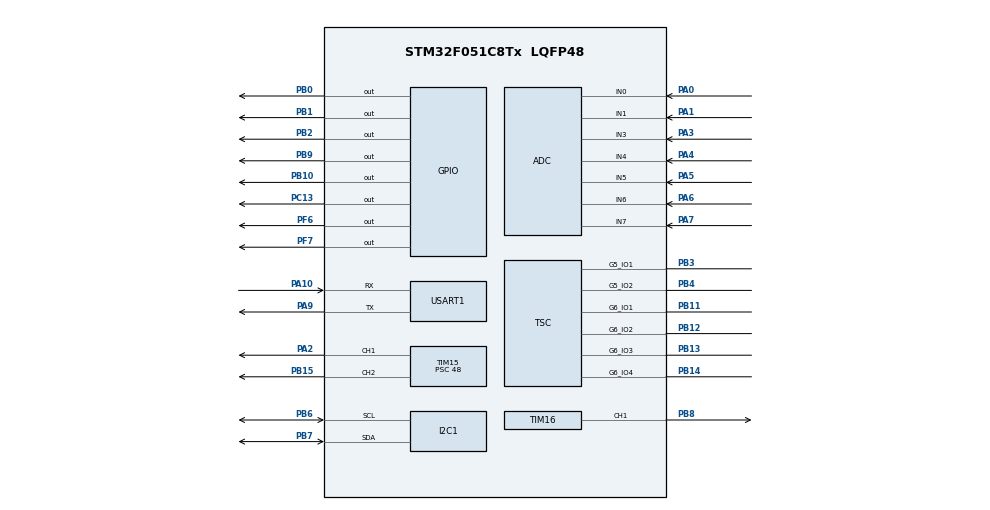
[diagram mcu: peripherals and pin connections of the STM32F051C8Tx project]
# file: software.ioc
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Mcu.Family=STM32F0
Mcu.Name=STM32F051C8Tx
Mcu.Package=LQFP48
Mcu.UserConstants=RS485_DE_HW_ENABLE,0
NVIC.USART1_IRQn=true\:0\:0\:false\:false\:true\:true
PA0.Mode=IN0
PA0.Signal=ADC_IN0
PA1.Mode=IN1
PA1.Signal=ADC_IN1
PA10.Mode=Asynchronous
PA10.Signal=USART1_RX
PA13.Mode=Serial_Wire
PA13.Signal=SYS_SWDIO
PA14.Mode=Serial_Wire
PA14.Signal=SYS_SWCLK
PA2.Signal=S_TIM15_CH1
PA3.Mode=IN3
PA3.Signal=ADC_IN3
PA4.Mode=IN4
PA4.Signal=ADC_IN4
PA5.Mode=IN5
PA5.Signal=ADC_IN5
PA6.Mode=IN6
PA6.Signal=ADC_IN6
PA7.Mode=IN7
PA7.Signal=ADC_IN7
PA9.Mode=Asynchronous
PA9.Signal=USART1_TX
PB0.Signal=GPIO_Output
PB1.Signal=GPIO_Output
PB10.Signal=GPIO_Output
PB11.Mode=G6_IO1-Sampling
PB11.Signal=TSC_G6_IO1
PB12.Mode=G6_IO2-Channel
PB12.Signal=TSC_G6_IO2
PB13.Mode=G6_IO3-Channel
PB13.Signal=TSC_G6_IO3
PB14.Mode=G6_IO4-Channel
PB14.Signal=TSC_G6_IO4
PB15.Signal=S_TIM15_CH2
PB2.Signal=GPIO_Output
PB3.Mode=G5_IO1-Sampling
PB3.Signal=TSC_G5_IO1
PB4.Mode=G5_IO2-Channel
PB4.Signal=TSC_G5_IO2
PB6.Mode=I2C
PB6.Signal=I2C1_SCL
PB7.Mode=I2C
PB7.Signal=I2C1_SDA
PB8.Signal=S_TIM16_CH1
PB9.Signal=GPIO_Output
PC13.Signal=GPIO_Output
PC14-OSC32_IN.Mode=LSE-External-Oscillator
PC14-OSC32_IN.Signal=RCC_OSC32_IN
PC15-OSC32_OUT.Mode=LSE-External-Oscillator
PC15-OSC32_OUT.Signal=RCC_OSC32_OUT
PF0-OSC_IN.Mode=HSE-External-Oscillator
PF0-OSC_IN.Signal=RCC_OSC_IN
PF1-OSC_OUT.Mode=HSE-External-Oscillator
PF1-OSC_OUT.Signal=RCC_OSC_OUT
PF6.Signal=GPIO_Output
PF7.Signal=GPIO_Output
ProjectManager.HeapSize=0x200
ProjectManager.StackSize=0x400
ProjectManager.TargetToolchain=Other Toolchains (GPDSC)
RCC.AHBFreq_Value=48000000
RCC.APB1Freq_Value=48000000
RCC.APB1TimFreq_Value=48000000
RCC.FLatency=FLASH_LATENCY_1
RCC.HCLKFreq_Value=48000000
RCC.PLLMUL=RCC_PLL_MUL6
RCC.PLLSourceVirtual=RCC_PLLSOURCE_HSE
RCC.RCC_MCOSource=RCC_MCO1SOURCE_PLLCLK_DIV2
RCC.SYSCLKFreq_VALUE=48000000
RCC.SYSCLKSource=RCC_SYSCLKSOURCE_PLLCLK
RCC.Usart1ClockSelection=RCC_USART1CLKSOURCE_SYSCLK
SH.S_TIM15_CH1.0=TIM15_CH1,PWM Generation1 CH1
SH.S_TIM15_CH2.0=TIM15_CH2,PWM Generation2 CH2
SH.S_TIM16_CH1.0=TIM16_CH1,PWM Generation1 CH1
TIM15.Channel-PWM\ Generation1\ CH1=TIM_CHANNEL_1
TIM15.Channel-PWM\ Generation2\ CH2=TIM_CHANNEL_2
TIM15.Period=1000
TIM15.Prescaler=48
TIM16.Channel=TIM_CHANNEL_1
TOUCHSENSING.IO_TOUCHKEY_B1=G5_IO2
TOUCHSENSING.IO_TOUCHKEY_B2=G6_IO2
TOUCHSENSING.IO_TOUCHKEY_B3=G6_IO3
TOUCHSENSING.IO_TOUCHKEY_B4=G6_IO4
TOUCHSENSING.TSLPRM_SENSORS_DATAS=TSLPRM_TOTAL_TOUCHKEYS_B 3 2 1 1 
TOUCHSENSING.TSLPRM_TOTAL_TOUCHKEYS_B=4
TSC.ChannelIOs-G5_IO2-Channel=TSC_GROUP5_IO2
TSC.ChannelIOs-G6_IO2-Channel=TSC_GROUP6_IO2
TSC.ChannelIOs-G6_IO3-Channel=TSC_GROUP6_IO3
TSC.ChannelIOs-G6_IO4-Channel=TSC_GROUP6_IO4
TSC.SamplingIOs-G5_IO1-Sampling=TSC_GROUP5_IO1
TSC.SamplingIOs-G6_IO1-Sampling=TSC_GROUP6_IO1
USART1.VirtualMode-Asynchronous=VM_ASYNC
VP_TIM16_VS_ClockSourceINT.Mode=Enable_Timer
VP_TOUCHSENSING_VS_TOUCHSENSING.Mode=TouchSensing_Enabled
board=template

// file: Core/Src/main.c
/**
  ******************************************************************************
  * @file           : main.c
  * @brief          : Main program body
  ******************************************************************************
  * This notice applies to any and all portions of this file
  * that are not between comment pairs USER CODE BEGIN and
  * USER CODE END. Other portions of this file, whether
  * inserted by the user or by software development tools
  * are owned by their respective copyright owners.
  *
  * Copyright (c) 2018 STMicroelectronics International N.V.
  * All rights reserved.
  *
  * Redistribution and use in source and binary forms, with or without
  * modification, are permitted, provided that the following conditions are met:
  *
  * 1. Redistribution of source code must retain the above copyright notice,
  *    this list of conditions and the following disclaimer.
  * 2. Redistributions in binary form must reproduce the above copyright notice,
  *    this list of conditions and the following disclaimer in the documentation
  *    and/or other materials provided with the distribution.
  * 3. Neither the name of STMicroelectronics nor the names of other
  *    contributors to this software may be used to endorse or promote products
  *    derived from this software without specific written permission.
  * 4. This software, including modifications and/or derivative works of this
  *    software, must execute solely and exclusively on microcontroller or
  *    microprocessor devices manufactured by or for STMicroelectronics.
  * 5. Redistribution and use of this software other than as permitted under
  *    this license is void and will automatically terminate your rights under
  *    this license.
  *
  * THIS SOFTWARE IS PROVIDED BY STMICROELECTRONICS AND CONTRIBUTORS "AS IS"
  * AND ANY EXPRESS, IMPLIED OR STATUTORY WARRANTIES, INCLUDING, BUT NOT
  * LIMITED TO, THE IMPLIED WARRANTIES OF MERCHANTABILITY, FITNESS FOR A
  * PARTICULAR PURPOSE AND NON-INFRINGEMENT OF THIRD PARTY INTELLECTUAL PROPERTY
  * RIGHTS ARE DISCLAIMED TO THE FULLEST EXTENT PERMITTED BY LAW. IN NO EVENT
  * SHALL STMICROELECTRONICS OR CONTRIBUTORS BE LIABLE FOR ANY DIRECT, INDIRECT,
  * INCIDENTAL, SPECIAL, EXEMPLARY, OR CONSEQUENTIAL DAMAGES (INCLUDING, BUT NOT
  * LIMITED TO, PROCUREMENT OF SUBSTITUTE GOODS OR SERVICES; LOSS OF USE, DATA,
  * OR PROFITS; OR BUSINESS INTERRUPTION) HOWEVER CAUSED AND ON ANY THEORY OF
  * LIABILITY, WHETHER IN CONTRACT, STRICT LIABILITY, OR TORT (INCLUDING
  * NEGLIGENCE OR OTHERWISE) ARISING IN ANY WAY OUT OF THE USE OF THIS SOFTWARE,
  * EVEN IF ADVISED OF THE POSSIBILITY OF SUCH DAMAGE.
  *
  ******************************************************************************
  */
#include "main.h"
#include "stm32f0xx_hal.h"
#include "touchsensing.h"

/* USER CODE BEGIN Includes */
#include "board.h"
/* USER CODE END Includes */

TSC_HandleTypeDef htsc;

/* USER CODE BEGIN PV */
volatile static uint32_t timestamp = 0, delay = 0;
/* Private variables ---------------------------------------------------------*/

/* USER CODE END PV */

void SystemClock_Config(void);
static void MX_GPIO_Init(void);
static void MX_I2C1_Init(void);
static void MX_USART1_UART_Init(void);
static void MX_TIM15_Init(void);
static void MX_TIM16_Init(void);
static void MX_TSC_Init(void);
static void MX_ADC_Init(void);

/* USER CODE BEGIN PFP */
/* Private function prototypes -----------------------------------------------*/

/* USER CODE END PFP */

int main(void)
{

  /* MCU Configuration----------------------------------------------------------*/

  /* Reset of all peripherals, Initializes the Flash interface and the Systick. */
  HAL_Init();

  /* Configure the system clock */
  SystemClock_Config();

  /* Initialize all configured peripherals */
  MX_GPIO_Init();
  MX_I2C1_Init();
  MX_USART1_UART_Init();
  MX_TIM15_Init();
  MX_TIM16_Init();
  MX_TSC_Init();
  MX_ADC_Init();
  MX_TOUCHSENSING_Init();
  /* USER CODE BEGIN 2 */

    UNI_Start();

    TSL_obj_GroupInit(&MyObjGroup);

  /* USER CODE END 2 */

  /* Infinite loop */
  /* USER CODE BEGIN WHILE */
  while (1)
  {
    timestamp = HAL_GetTick();

    if(delay < timestamp){

        delay = timestamp + 100;

        LED2_TOGGLE();
    }

    TSL_obj_GroupProcess(&MyObjGroup);
  /* USER CODE END WHILE */

  }

}

void SystemClock_Config(void)
{

  LL_FLASH_SetLatency(LL_FLASH_LATENCY_1);

  if(LL_FLASH_GetLatency() != LL_FLASH_LATENCY_1)
  {
  Error_Handler();
  }
  LL_RCC_HSE_Enable();

   /* Wait till HSE is ready */
  while(LL_RCC_HSE_IsReady() != 1)
  {

  }
  LL_RCC_HSI_Enable();

   /* Wait till HSI is ready */
  while(LL_RCC_HSI_IsReady() != 1)
  {

  }
  LL_RCC_HSI_SetCalibTrimming(16);

  LL_RCC_HSI14_Enable();

   /* Wait till HSI14 is ready */
  while(LL_RCC_HSI14_IsReady() != 1)
  {

  }
  LL_RCC_HSI14_SetCalibTrimming(16);

  LL_RCC_PLL_ConfigDomain_SYS(LL_RCC_PLLSOURCE_HSE_DIV_1, LL_RCC_PLL_MUL_6);

  LL_RCC_PLL_Enable();

   /* Wait till PLL is ready */
  while(LL_RCC_PLL_IsReady() != 1)
  {

  }
  LL_RCC_SetAHBPrescaler(LL_RCC_SYSCLK_DIV_1);

  LL_RCC_SetAPB1Prescaler(LL_RCC_APB1_DIV_1);

  LL_RCC_SetSysClkSource(LL_RCC_SYS_CLKSOURCE_PLL);

   /* Wait till System clock is ready */
  while(LL_RCC_GetSysClkSource() != LL_RCC_SYS_CLKSOURCE_STATUS_PLL)
  {

  }
  LL_Init1msTick(48000000);

  LL_SYSTICK_SetClkSource(LL_SYSTICK_CLKSOURCE_HCLK);

  LL_SetSystemCoreClock(48000000);

  LL_RCC_HSI14_EnableADCControl();

  LL_RCC_SetUSARTClockSource(LL_RCC_USART1_CLKSOURCE_SYSCLK);

  LL_RCC_SetI2CClockSource(LL_RCC_I2C1_CLKSOURCE_HSI);

  /* SysTick_IRQn interrupt configuration */
  NVIC_SetPriority(SysTick_IRQn, 0);
}

/* ADC init function */
static void MX_ADC_Init(void)
{

  LL_ADC_InitTypeDef ADC_InitStruct;
  LL_ADC_REG_InitTypeDef ADC_REG_InitStruct;

  LL_GPIO_InitTypeDef GPIO_InitStruct;

  /* Peripheral clock enable */
  LL_APB1_GRP2_EnableClock(LL_APB1_GRP2_PERIPH_ADC1);

  /**ADC GPIO Configuration
  PA0   ------> ADC_IN0
  PA1   ------> ADC_IN1
  PA3   ------> ADC_IN3
  PA4   ------> ADC_IN4
  PA5   ------> ADC_IN5
  PA6   ------> ADC_IN6
  PA7   ------> ADC_IN7
  */
  GPIO_InitStruct.Pin = LL_GPIO_PIN_0;
  GPIO_InitStruct.Mode = LL_GPIO_MODE_ANALOG;
  GPIO_InitStruct.Pull = LL_GPIO_PULL_NO;
  LL_GPIO_Init(GPIOA, &GPIO_InitStruct);

  GPIO_InitStruct.Pin = LL_GPIO_PIN_1;
  GPIO_InitStruct.Mode = LL_GPIO_MODE_ANALOG;
  GPIO_InitStruct.Pull = LL_GPIO_PULL_NO;
  LL_GPIO_Init(GPIOA, &GPIO_InitStruct);

  GPIO_InitStruct.Pin = LL_GPIO_PIN_3;
  GPIO_InitStruct.Mode = LL_GPIO_MODE_ANALOG;
  GPIO_InitStruct.Pull = LL_GPIO_PULL_NO;
  LL_GPIO_Init(GPIOA, &GPIO_InitStruct);

  GPIO_InitStruct.Pin = LL_GPIO_PIN_4;
  GPIO_InitStruct.Mode = LL_GPIO_MODE_ANALOG;
  GPIO_InitStruct.Pull = LL_GPIO_PULL_NO;
  LL_GPIO_Init(GPIOA, &GPIO_InitStruct);

  GPIO_InitStruct.Pin = LL_GPIO_PIN_5;
  GPIO_InitStruct.Mode = LL_GPIO_MODE_ANALOG;
  GPIO_InitStruct.Pull = LL_GPIO_PULL_NO;
  LL_GPIO_Init(GPIOA, &GPIO_InitStruct);

  GPIO_InitStruct.Pin = LL_GPIO_PIN_6;
  GPIO_InitStruct.Mode = LL_GPIO_MODE_ANALOG;
  GPIO_InitStruct.Pull = LL_GPIO_PULL_NO;
  LL_GPIO_Init(GPIOA, &GPIO_InitStruct);

  GPIO_InitStruct.Pin = LL_GPIO_PIN_7;
  GPIO_InitStruct.Mode = LL_GPIO_MODE_ANALOG;
  GPIO_InitStruct.Pull = LL_GPIO_PULL_NO;
  LL_GPIO_Init(GPIOA, &GPIO_InitStruct);

    /**Configure Regular Channel
    */
  LL_ADC_REG_SetSequencerChAdd(ADC1, LL_ADC_CHANNEL_0);

    /**Configure Regular Channel
    */
  LL_ADC_REG_SetSequencerChAdd(ADC1, LL_ADC_CHANNEL_1);

    /**Configure Regular Channel
    */
  LL_ADC_REG_SetSequencerChAdd(ADC1, LL_ADC_CHANNEL_3);

    /**Configure Regular Channel
    */
  LL_ADC_REG_SetSequencerChAdd(ADC1, LL_ADC_CHANNEL_4);

    /**Configure Regular Channel
    */
  LL_ADC_REG_SetSequencerChAdd(ADC1, LL_ADC_CHANNEL_5);

    /**Configure Regular Channel
    */
  LL_ADC_REG_SetSequencerChAdd(ADC1, LL_ADC_CHANNEL_6);

    /**Configure Regular Channel
    */
  LL_ADC_REG_SetSequencerChAdd(ADC1, LL_ADC_CHANNEL_7);

    /**Configure the global features of the ADC (Clock, Resolution, Data Alignment and number of conversion)
    */
  ADC_InitStruct.Clock = LL_ADC_CLOCK_ASYNC;
  ADC_InitStruct.Resolution = LL_ADC_RESOLUTION_12B;
  ADC_InitStruct.DataAlignment = LL_ADC_DATA_ALIGN_RIGHT;
  ADC_InitStruct.LowPowerMode = LL_ADC_LP_MODE_NONE;
  LL_ADC_Init(ADC1, &ADC_InitStruct);

  ADC_REG_InitStruct.TriggerSource = LL_ADC_REG_TRIG_SOFTWARE;
  ADC_REG_InitStruct.SequencerDiscont = LL_ADC_REG_SEQ_DISCONT_DISABLE;
  ADC_REG_InitStruct.ContinuousMode = LL_ADC_REG_CONV_SINGLE;
  ADC_REG_InitStruct.DMATransfer = LL_ADC_REG_DMA_TRANSFER_LIMITED;
  ADC_REG_InitStruct.Overrun = LL_ADC_REG_OVR_DATA_PRESERVED;
  LL_ADC_REG_Init(ADC1, &ADC_REG_InitStruct);

  LL_ADC_REG_SetSequencerScanDirection(ADC1, LL_ADC_REG_SEQ_SCAN_DIR_FORWARD);

  LL_ADC_SetSamplingTimeCommonChannels(ADC1, LL_ADC_SAMPLINGTIME_1CYCLE_5);

  LL_ADC_DisableIT_EOC(ADC1);

  LL_ADC_DisableIT_EOS(ADC1);

}

/* I2C1 init function */
static void MX_I2C1_Init(void)
{

  LL_I2C_InitTypeDef I2C_InitStruct;

  LL_GPIO_InitTypeDef GPIO_InitStruct;

  /**I2C1 GPIO Configuration
  PB6   ------> I2C1_SCL
  PB7   ------> I2C1_SDA
  */
  GPIO_InitStruct.Pin = LL_GPIO_PIN_6;
  GPIO_InitStruct.Mode = LL_GPIO_MODE_ALTERNATE;
  GPIO_InitStruct.Speed = LL_GPIO_SPEED_FREQ_HIGH;
  GPIO_InitStruct.OutputType = LL_GPIO_OUTPUT_OPENDRAIN;
  GPIO_InitStruct.Pull = LL_GPIO_PULL_UP;
  GPIO_InitStruct.Alternate = LL_GPIO_AF_1;
  LL_GPIO_Init(GPIOB, &GPIO_InitStruct);

  GPIO_InitStruct.Pin = LL_GPIO_PIN_7;
  GPIO_InitStruct.Mode = LL_GPIO_MODE_ALTERNATE;
  GPIO_InitStruct.Speed = LL_GPIO_SPEED_FREQ_HIGH;
  GPIO_InitStruct.OutputType = LL_GPIO_OUTPUT_OPENDRAIN;
  GPIO_InitStruct.Pull = LL_GPIO_PULL_UP;
  GPIO_InitStruct.Alternate = LL_GPIO_AF_1;
  LL_GPIO_Init(GPIOB, &GPIO_InitStruct);

  /* Peripheral clock enable */
  LL_APB1_GRP1_EnableClock(LL_APB1_GRP1_PERIPH_I2C1);

    /**I2C Initialization
    */
  LL_I2C_DisableOwnAddress2(I2C1);

  LL_I2C_DisableGeneralCall(I2C1);

  LL_I2C_EnableClockStretching(I2C1);

  I2C_InitStruct.PeripheralMode = LL_I2C_MODE_I2C;
  I2C_InitStruct.Timing = 0x2000090E;
  I2C_InitStruct.AnalogFilter = LL_I2C_ANALOGFILTER_ENABLE;
  I2C_InitStruct.DigitalFilter = 0;
  I2C_InitStruct.OwnAddress1 = 0;
  I2C_InitStruct.TypeAcknowledge = LL_I2C_ACK;
  I2C_InitStruct.OwnAddrSize = LL_I2C_OWNADDRESS1_7BIT;
  LL_I2C_Init(I2C1, &I2C_InitStruct);

  LL_I2C_EnableAutoEndMode(I2C1);

  LL_I2C_SetOwnAddress2(I2C1, 0, LL_I2C_OWNADDRESS2_NOMASK);

}

/* TIM15 init function */
static void MX_TIM15_Init(void)
{

  LL_TIM_InitTypeDef TIM_InitStruct;
  LL_TIM_OC_InitTypeDef TIM_OC_InitStruct;
  LL_TIM_BDTR_InitTypeDef TIM_BDTRInitStruct;

  LL_GPIO_InitTypeDef GPIO_InitStruct;

  /* Peripheral clock enable */
  LL_APB1_GRP2_EnableClock(LL_APB1_GRP2_PERIPH_TIM15);

  TIM_InitStruct.Prescaler = 48;
  TIM_InitStruct.CounterMode = LL_TIM_COUNTERMODE_UP;
  TIM_InitStruct.Autoreload = 1000;
  TIM_InitStruct.ClockDivision = LL_TIM_CLOCKDIVISION_DIV1;
  TIM_InitStruct.RepetitionCounter = 0;
  LL_TIM_Init(TIM15, &TIM_InitStruct);

  LL_TIM_DisableARRPreload(TIM15);

  LL_TIM_OC_EnablePreload(TIM15, LL_TIM_CHANNEL_CH1);

  TIM_OC_InitStruct.OCMode = LL_TIM_OCMODE_PWM1;
  TIM_OC_InitStruct.OCState = LL_TIM_OCSTATE_DISABLE;
  TIM_OC_InitStruct.OCNState = LL_TIM_OCSTATE_DISABLE;
  TIM_OC_InitStruct.CompareValue = 0;
  TIM_OC_InitStruct.OCPolarity = LL_TIM_OCPOLARITY_HIGH;
  TIM_OC_InitStruct.OCNPolarity = LL_TIM_OCPOLARITY_HIGH;
  TIM_OC_InitStruct.OCIdleState = LL_TIM_OCIDLESTATE_LOW;
  TIM_OC_InitStruct.OCNIdleState = LL_TIM_OCIDLESTATE_LOW;
  LL_TIM_OC_Init(TIM15, LL_TIM_CHANNEL_CH1, &TIM_OC_InitStruct);

  LL_TIM_OC_DisableFast(TIM15, LL_TIM_CHANNEL_CH1);

  LL_TIM_OC_EnablePreload(TIM15, LL_TIM_CHANNEL_CH2);

  TIM_OC_InitStruct.OCState = LL_TIM_OCSTATE_DISABLE;
  TIM_OC_InitStruct.OCNState = LL_TIM_OCSTATE_DISABLE;
  LL_TIM_OC_Init(TIM15, LL_TIM_CHANNEL_CH2, &TIM_OC_InitStruct);

  LL_TIM_OC_DisableFast(TIM15, LL_TIM_CHANNEL_CH2);

  LL_TIM_SetTriggerOutput(TIM15, LL_TIM_TRGO_RESET);

  LL_TIM_DisableMasterSlaveMode(TIM15);

  TIM_BDTRInitStruct.OSSRState = LL_TIM_OSSR_DISABLE;
  TIM_BDTRInitStruct.OSSIState = LL_TIM_OSSI_DISABLE;
  TIM_BDTRInitStruct.LockLevel = LL_TIM_LOCKLEVEL_OFF;
  TIM_BDTRInitStruct.DeadTime = 0;
  TIM_BDTRInitStruct.BreakState = LL_TIM_BREAK_DISABLE;
  TIM_BDTRInitStruct.BreakPolarity = LL_TIM_BREAK_POLARITY_HIGH;
  TIM_BDTRInitStruct.AutomaticOutput = LL_TIM_AUTOMATICOUTPUT_DISABLE;
  LL_TIM_BDTR_Init(TIM15, &TIM_BDTRInitStruct);

  /**TIM15 GPIO Configuration
  PA2   ------> TIM15_CH1
  PB15   ------> TIM15_CH2
  */
  GPIO_InitStruct.Pin = LL_GPIO_PIN_2;
  GPIO_InitStruct.Mode = LL_GPIO_MODE_ALTERNATE;
  GPIO_InitStruct.Speed = LL_GPIO_SPEED_FREQ_LOW;
  GPIO_InitStruct.OutputType = LL_GPIO_OUTPUT_PUSHPULL;
  GPIO_InitStruct.Pull = LL_GPIO_PULL_NO;
  GPIO_InitStruct.Alternate = LL_GPIO_AF_0;
  LL_GPIO_Init(GPIOA, &GPIO_InitStruct);

  GPIO_InitStruct.Pin = LL_GPIO_PIN_15;
  GPIO_InitStruct.Mode = LL_GPIO_MODE_ALTERNATE;
  GPIO_InitStruct.Speed = LL_GPIO_SPEED_FREQ_LOW;
  GPIO_InitStruct.OutputType = LL_GPIO_OUTPUT_PUSHPULL;
  GPIO_InitStruct.Pull = LL_GPIO_PULL_NO;
  GPIO_InitStruct.Alternate = LL_GPIO_AF_1;
  LL_GPIO_Init(GPIOB, &GPIO_InitStruct);

}

/* TIM16 init function */
static void MX_TIM16_Init(void)
{

  LL_TIM_InitTypeDef TIM_InitStruct;
  LL_TIM_OC_InitTypeDef TIM_OC_InitStruct;
  LL_TIM_BDTR_InitTypeDef TIM_BDTRInitStruct;

  LL_GPIO_InitTypeDef GPIO_InitStruct;

  /* Peripheral clock enable */
  LL_APB1_GRP2_EnableClock(LL_APB1_GRP2_PERIPH_TIM16);

  TIM_InitStruct.Prescaler = 0;
  TIM_InitStruct.CounterMode = LL_TIM_COUNTERMODE_UP;
  TIM_InitStruct.Autoreload = 0;
  TIM_InitStruct.ClockDivision = LL_TIM_CLOCKDIVISION_DIV1;
  TIM_InitStruct.RepetitionCounter = 0;
  LL_TIM_Init(TIM16, &TIM_InitStruct);

  LL_TIM_DisableARRPreload(TIM16);

  LL_TIM_OC_EnablePreload(TIM16, LL_TIM_CHANNEL_CH1);

  TIM_OC_InitStruct.OCMode = LL_TIM_OCMODE_PWM1;
  TIM_OC_InitStruct.OCState = LL_TIM_OCSTATE_DISABLE;
  TIM_OC_InitStruct.OCNState = LL_TIM_OCSTATE_DISABLE;
  TIM_OC_InitStruct.CompareValue = 0;
  TIM_OC_InitStruct.OCPolarity = LL_TIM_OCPOLARITY_HIGH;
  TIM_OC_InitStruct.OCNPolarity = LL_TIM_OCPOLARITY_HIGH;
  TIM_OC_InitStruct.OCIdleState = LL_TIM_OCIDLESTATE_LOW;
  TIM_OC_InitStruct.OCNIdleState = LL_TIM_OCIDLESTATE_LOW;
  LL_TIM_OC_Init(TIM16, LL_TIM_CHANNEL_CH1, &TIM_OC_InitStruct);

  LL_TIM_OC_DisableFast(TIM16, LL_TIM_CHANNEL_CH1);

  TIM_BDTRInitStruct.OSSRState = LL_TIM_OSSR_DISABLE;
  TIM_BDTRInitStruct.OSSIState = LL_TIM_OSSI_DISABLE;
  TIM_BDTRInitStruct.LockLevel = LL_TIM_LOCKLEVEL_OFF;
  TIM_BDTRInitStruct.DeadTime = 0;
  TIM_BDTRInitStruct.BreakState = LL_TIM_BREAK_DISABLE;
  TIM_BDTRInitStruct.BreakPolarity = LL_TIM_BREAK_POLARITY_HIGH;
  TIM_BDTRInitStruct.AutomaticOutput = LL_TIM_AUTOMATICOUTPUT_DISABLE;
  LL_TIM_BDTR_Init(TIM16, &TIM_BDTRInitStruct);

  /**TIM16 GPIO Configuration
  PB8   ------> TIM16_CH1
  */
  GPIO_InitStruct.Pin = LL_GPIO_PIN_8;
  GPIO_InitStruct.Mode = LL_GPIO_MODE_ALTERNATE;
  GPIO_InitStruct.Speed = LL_GPIO_SPEED_FREQ_LOW;
  GPIO_InitStruct.OutputType = LL_GPIO_OUTPUT_PUSHPULL;
  GPIO_InitStruct.Pull = LL_GPIO_PULL_NO;
  GPIO_InitStruct.Alternate = LL_GPIO_AF_2;
  LL_GPIO_Init(GPIOB, &GPIO_InitStruct);

}

/* TSC init function */
static void MX_TSC_Init(void)
{

    /**Configure the TSC peripheral
    */
  htsc.Instance = TSC;
  htsc.Init.CTPulseHighLength = TSC_CTPH_2CYCLES;
  htsc.Init.CTPulseLowLength = TSC_CTPL_2CYCLES;
  htsc.Init.SpreadSpectrum = DISABLE;
  htsc.Init.SpreadSpectrumDeviation = 1;
  htsc.Init.SpreadSpectrumPrescaler = TSC_SS_PRESC_DIV1;
  htsc.Init.PulseGeneratorPrescaler = TSC_PG_PRESC_DIV4;
  htsc.Init.MaxCountValue = TSC_MCV_8191;
  htsc.Init.IODefaultMode = TSC_IODEF_OUT_PP_LOW;
  htsc.Init.SynchroPinPolarity = TSC_SYNC_POLARITY_FALLING;
  htsc.Init.AcquisitionMode = TSC_ACQ_MODE_NORMAL;
  htsc.Init.MaxCountInterrupt = DISABLE;
  htsc.Init.ChannelIOs = TSC_GROUP5_IO2|TSC_GROUP6_IO2|TSC_GROUP6_IO3|TSC_GROUP6_IO4;
  htsc.Init.ShieldIOs = 0;
  htsc.Init.SamplingIOs = TSC_GROUP5_IO1|TSC_GROUP6_IO1;
  if (HAL_TSC_Init(&htsc) != HAL_OK)
  {
    _Error_Handler(__FILE__, __LINE__);
  }

}

/* USART1 init function */
static void MX_USART1_UART_Init(void)
{

  LL_USART_InitTypeDef USART_InitStruct;

  LL_GPIO_InitTypeDef GPIO_InitStruct;

  /* Peripheral clock enable */
  LL_APB1_GRP2_EnableClock(LL_APB1_GRP2_PERIPH_USART1);

  /**USART1 GPIO Configuration
  PA9   ------> USART1_TX
  PA10   ------> USART1_RX
  */
  GPIO_InitStruct.Pin = LL_GPIO_PIN_9;
  GPIO_InitStruct.Mode = LL_GPIO_MODE_ALTERNATE;
  GPIO_InitStruct.Speed = LL_GPIO_SPEED_FREQ_HIGH;
  GPIO_InitStruct.OutputType = LL_GPIO_OUTPUT_PUSHPULL;
  GPIO_InitStruct.Pull = LL_GPIO_PULL_NO;
  GPIO_InitStruct.Alternate = LL_GPIO_AF_1;
  LL_GPIO_Init(GPIOA, &GPIO_InitStruct);

  GPIO_InitStruct.Pin = LL_GPIO_PIN_10;
  GPIO_InitStruct.Mode = LL_GPIO_MODE_ALTERNATE;
  GPIO_InitStruct.Speed = LL_GPIO_SPEED_FREQ_HIGH;
  GPIO_InitStruct.OutputType = LL_GPIO_OUTPUT_PUSHPULL;
  GPIO_InitStruct.Pull = LL_GPIO_PULL_NO;
  GPIO_InitStruct.Alternate = LL_GPIO_AF_1;
  LL_GPIO_Init(GPIOA, &GPIO_InitStruct);

  /* USART1 interrupt Init */
  NVIC_SetPriority(USART1_IRQn, 0);
  NVIC_EnableIRQ(USART1_IRQn);

  USART_InitStruct.BaudRate = 38400;
  USART_InitStruct.DataWidth = LL_USART_DATAWIDTH_8B;
  USART_InitStruct.StopBits = LL_USART_STOPBITS_1;
  USART_InitStruct.Parity = LL_USART_PARITY_NONE;
  USART_InitStruct.TransferDirection = LL_USART_DIRECTION_TX_RX;
  USART_InitStruct.HardwareFlowControl = LL_USART_HWCONTROL_NONE;
  USART_InitStruct.OverSampling = LL_USART_OVERSAMPLING_16;
  LL_USART_Init(USART1, &USART_InitStruct);

  LL_USART_DisableIT_CTS(USART1);

  LL_USART_DisableOverrunDetect(USART1);

  LL_USART_ConfigAsyncMode(USART1);

  LL_USART_Enable(USART1);

}

/** Configure pins as
        * Analog
        * Input
        * Output
        * EVENT_OUT
        * EXTI
*/
static void MX_GPIO_Init(void)
{

  LL_GPIO_InitTypeDef GPIO_InitStruct;

  /* GPIO Ports Clock Enable */
  LL_AHB1_GRP1_EnableClock(LL_AHB1_GRP1_PERIPH_GPIOC);
  LL_AHB1_GRP1_EnableClock(LL_AHB1_GRP1_PERIPH_GPIOF);
  LL_AHB1_GRP1_EnableClock(LL_AHB1_GRP1_PERIPH_GPIOA);
  LL_AHB1_GRP1_EnableClock(LL_AHB1_GRP1_PERIPH_GPIOB);

  /**/
  LL_GPIO_ResetOutputPin(GPIOC, LL_GPIO_PIN_13);

  /**/
  LL_GPIO_ResetOutputPin(GPIOB, LL_GPIO_PIN_0);

  /**/
  LL_GPIO_ResetOutputPin(GPIOB, LL_GPIO_PIN_1);

  /**/
  LL_GPIO_ResetOutputPin(GPIOB, LL_GPIO_PIN_2);

  /**/
  LL_GPIO_ResetOutputPin(GPIOB, LL_GPIO_PIN_10);

  /**/
  LL_GPIO_ResetOutputPin(GPIOF, LL_GPIO_PIN_6);

  /**/
  LL_GPIO_ResetOutputPin(GPIOF, LL_GPIO_PIN_7);

  /**/
  LL_GPIO_ResetOutputPin(GPIOB, LL_GPIO_PIN_9);

  /**/
  GPIO_InitStruct.Pin = LL_GPIO_PIN_13;
  GPIO_InitStruct.Mode = LL_GPIO_MODE_OUTPUT;
  GPIO_InitStruct.Speed = LL_GPIO_SPEED_FREQ_LOW;
  GPIO_InitStruct.OutputType = LL_GPIO_OUTPUT_PUSHPULL;
  GPIO_InitStruct.Pull = LL_GPIO_PULL_NO;
  LL_GPIO_Init(GPIOC, &GPIO_InitStruct);

  /**/
  GPIO_InitStruct.Pin = LL_GPIO_PIN_0;
  GPIO_InitStruct.Mode = LL_GPIO_MODE_OUTPUT;
  GPIO_InitStruct.Speed = LL_GPIO_SPEED_FREQ_LOW;
  GPIO_InitStruct.OutputType = LL_GPIO_OUTPUT_PUSHPULL;
  GPIO_InitStruct.Pull = LL_GPIO_PULL_NO;
  LL_GPIO_Init(GPIOB, &GPIO_InitStruct);

  /**/
  GPIO_InitStruct.Pin = LL_GPIO_PIN_1;
  GPIO_InitStruct.Mode = LL_GPIO_MODE_OUTPUT;
  GPIO_InitStruct.Speed = LL_GPIO_SPEED_FREQ_LOW;
  GPIO_InitStruct.OutputType = LL_GPIO_OUTPUT_PUSHPULL;
  GPIO_InitStruct.Pull = LL_GPIO_PULL_NO;
  LL_GPIO_Init(GPIOB, &GPIO_InitStruct);

  /**/
  GPIO_InitStruct.Pin = LL_GPIO_PIN_2;
  GPIO_InitStruct.Mode = LL_GPIO_MODE_OUTPUT;
  GPIO_InitStruct.Speed = LL_GPIO_SPEED_FREQ_LOW;
  GPIO_InitStruct.OutputType = LL_GPIO_OUTPUT_PUSHPULL;
  GPIO_InitStruct.Pull = LL_GPIO_PULL_NO;
  LL_GPIO_Init(GPIOB, &GPIO_InitStruct);

  /**/
  GPIO_InitStruct.Pin = LL_GPIO_PIN_10;
  GPIO_InitStruct.Mode = LL_GPIO_MODE_OUTPUT;
  GPIO_InitStruct.Speed = LL_GPIO_SPEED_FREQ_LOW;
  GPIO_InitStruct.OutputType = LL_GPIO_OUTPUT_PUSHPULL;
  GPIO_InitStruct.Pull = LL_GPIO_PULL_NO;
  LL_GPIO_Init(GPIOB, &GPIO_InitStruct);

  /**/
  GPIO_InitStruct.Pin = LL_GPIO_PIN_6;
  GPIO_InitStruct.Mode = LL_GPIO_MODE_OUTPUT;
  GPIO_InitStruct.Speed = LL_GPIO_SPEED_FREQ_LOW;
  GPIO_InitStruct.OutputType = LL_GPIO_OUTPUT_PUSHPULL;
  GPIO_InitStruct.Pull = LL_GPIO_PULL_NO;
  LL_GPIO_Init(GPIOF, &GPIO_InitStruct);

  /**/
  GPIO_InitStruct.Pin = LL_GPIO_PIN_7;
  GPIO_InitStruct.Mode = LL_GPIO_MODE_OUTPUT;
  GPIO_InitStruct.Speed = LL_GPIO_SPEED_FREQ_LOW;
  GPIO_InitStruct.OutputType = LL_GPIO_OUTPUT_PUSHPULL;
  GPIO_InitStruct.Pull = LL_GPIO_PULL_NO;
  LL_GPIO_Init(GPIOF, &GPIO_InitStruct);

  /**/
  GPIO_InitStruct.Pin = LL_GPIO_PIN_9;
  GPIO_InitStruct.Mode = LL_GPIO_MODE_OUTPUT;
  GPIO_InitStruct.Speed = LL_GPIO_SPEED_FREQ_LOW;
  GPIO_InitStruct.OutputType = LL_GPIO_OUTPUT_PUSHPULL;
  GPIO_InitStruct.Pull = LL_GPIO_PULL_NO;
  LL_GPIO_Init(GPIOB, &GPIO_InitStruct);

}

void _Error_Handler(char *file, int line)
{
  while(1)
  {
  }
}

/************************ (C) COPYRIGHT STMicroelectronics *****END OF FILE****/
